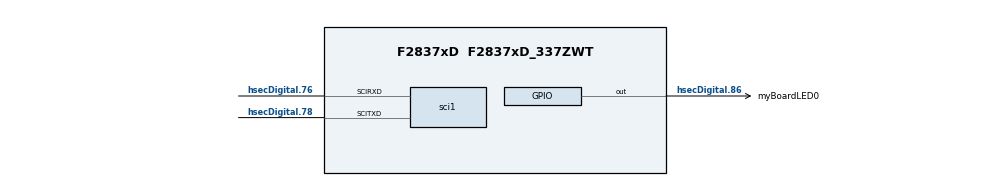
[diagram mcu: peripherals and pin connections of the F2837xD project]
/**
 * @cliArgs --board "/boards/TMDSCNCD28379D" --device "F2837xD" --part "F2837xD_337ZWT" --package "F2837xD_337ZWT" --context "CPU1" --product "C2000WARE@6.00.01.00"
 * @versions {"tool":"1.26.0+4407"}
 */

/**
 * Import the modules used in this configuration.
 */
const adc            = scripting.addModule("/driverlib/adc.js", {}, false);
const adc1           = adc.addInstance();
const adc2           = adc.addInstance();
const adc3           = adc.addInstance();
const adc4           = adc.addInstance();
const led            = scripting.addModule("/driverlib/board_components/led", {}, false);
const led1           = led.addInstance();
const device_support = scripting.addModule("/driverlib/device_support.js");
const epwm           = scripting.addModule("/driverlib/epwm.js", {}, false);
const epwm1          = epwm.addInstance();
const epwm2          = epwm.addInstance();
const epwm3          = epwm.addInstance();
const epwm4          = epwm.addInstance();
const epwm5          = epwm.addInstance();
const epwm6          = epwm.addInstance();
const epwm7          = epwm.addInstance();
const epwm8          = epwm.addInstance();
const inputxbar      = scripting.addModule("/driverlib/inputxbar.js", {}, false);
const inputxbar1     = inputxbar.addInstance();
const sci            = scripting.addModule("/driverlib/sci.js", {}, false);
const sci1           = sci.addInstance();

/**
 * Write custom configuration values to the imported modules.
 */
adc1.$name                   = "myADC0";
adc1.adcClockPrescaler       = "ADC_CLK_DIV_4_0";
adc1.enableInterrupt1        = true;
adc1.interruptPulseMode      = "ADC_PULSE_END_OF_CONV";
adc1.soc3SampleWindow        = 15;
adc1.soc4SampleWindow        = 15;
adc1.soc5SampleWindow        = 15;
adc1.soc6SampleWindow        = 15;
adc1.soc7SampleWindow        = 15;
adc1.soc8SampleWindow        = 15;
adc1.soc9SampleWindow        = 15;
adc1.soc10SampleWindow       = 15;
adc1.soc11SampleWindow       = 15;
adc1.soc12SampleWindow       = 15;
adc1.soc13SampleWindow       = 15;
adc1.soc14SampleWindow       = 15;
adc1.soc15SampleWindow       = 15;
adc1.soc0Trigger             = "ADC_TRIGGER_EPWM1_SOCA";
adc1.soc1Trigger             = "ADC_TRIGGER_EPWM1_SOCB";
adc1.enableInterrupt2        = true;
adc1.interrupt2SOCSource     = "ADC_SOC_NUMBER1";
adc1.soc2Trigger             = "ADC_TRIGGER_EPWM2_SOCA";
adc1.enableInterrupt3        = true;
adc1.interrupt3SOCSource     = "ADC_SOC_NUMBER2";
adc1.enabledSOCs             = ["ADC_SOC_NUMBER0","ADC_SOC_NUMBER1","ADC_SOC_NUMBER2"];
adc1.enabledInts             = ["ADC_INT_NUMBER1","ADC_INT_NUMBER2","ADC_INT_NUMBER3"];
adc1.registerInterrupts      = ["1","2","3"];
adc1.soc1Channel             = "ADC_CH_ADCIN2";
adc1.soc2Channel             = "ADC_CH_ADCIN4";
adc1.adcInt1.enableInterrupt = true;
adc1.adcInt2.enableInterrupt = true;
adc1.adcInt3.enableInterrupt = true;
scripting.suppress("SOC0 sample window must be at least 15", adc1, "soc0SampleWindow");
scripting.suppress("SOC1 sample window must be at least 15", adc1, "soc1SampleWindow");
scripting.suppress("SOC2 sample window must be at least 15", adc1, "soc2SampleWindow");

adc2.$name                   = "myADC1";
adc2.adcClockPrescaler       = "ADC_CLK_DIV_4_0";
adc2.enableInterrupt1        = true;
adc2.interruptPulseMode      = "ADC_PULSE_END_OF_CONV";
adc2.soc4SampleWindow        = 15;
adc2.soc5SampleWindow        = 15;
adc2.soc6SampleWindow        = 15;
adc2.soc7SampleWindow        = 15;
adc2.soc10SampleWindow       = 15;
adc2.soc11SampleWindow       = 15;
adc2.soc12SampleWindow       = 15;
adc2.soc13SampleWindow       = 15;
adc2.soc14SampleWindow       = 15;
adc2.soc15SampleWindow       = 15;
adc2.soc0Trigger             = "ADC_TRIGGER_EPWM1_SOCA";
adc2.soc1Channel             = "ADC_CH_ADCIN2";
adc2.soc1Trigger             = "ADC_TRIGGER_EPWM1_SOCB";
adc2.enableInterrupt2        = true;
adc2.soc2Channel             = "ADC_CH_ADCIN4";
adc2.soc2Trigger             = "ADC_TRIGGER_EPWM2_SOCA";
adc2.enableInterrupt3        = true;
adc2.adcBase                 = "ADCB_BASE";
adc2.enabledInts             = ["ADC_INT_NUMBER1","ADC_INT_NUMBER2","ADC_INT_NUMBER3"];
adc2.registerInterrupts      = ["1","2","3"];
adc2.enabledSOCs             = ["ADC_SOC_NUMBER3","ADC_SOC_NUMBER8","ADC_SOC_NUMBER9"];
adc2.soc3Trigger             = "ADC_TRIGGER_EPWM2_SOCB";
adc2.soc8Trigger             = "ADC_TRIGGER_EPWM5_SOCA";
adc2.soc9Trigger             = "ADC_TRIGGER_EPWM5_SOCB";
adc2.interrupt1SOCSource     = "ADC_SOC_NUMBER3";
adc2.interrupt2SOCSource     = "ADC_SOC_NUMBER8";
adc2.interrupt3SOCSource     = "ADC_SOC_NUMBER9";
adc2.soc8Channel             = "ADC_CH_ADCIN2";
adc2.soc9Channel             = "ADC_CH_ADCIN4";
adc2.adcInt1.enableInterrupt = true;
adc2.adcInt2.enableInterrupt = true;
adc2.adcInt3.enableInterrupt = true;
scripting.suppress("SOC3 sample window must be at least 15", adc2, "soc3SampleWindow");
scripting.suppress("SOC8 sample window must be at least 15", adc2, "soc8SampleWindow");
scripting.suppress("SOC9 sample window must be at least 15", adc2, "soc9SampleWindow");

adc3.$name                          = "myADC2";
adc3.adcClockPrescaler              = "ADC_CLK_DIV_4_0";
adc3.enableInterrupt1               = true;
adc3.interruptPulseMode             = "ADC_PULSE_END_OF_CONV";
adc3.soc3SampleWindow               = 15;
adc3.soc4SampleWindow               = 15;
adc3.soc5SampleWindow               = 15;
adc3.soc6SampleWindow               = 15;
adc3.soc7SampleWindow               = 15;
adc3.soc8SampleWindow               = 15;
adc3.soc9SampleWindow               = 15;
adc3.soc11SampleWindow              = 15;
adc3.soc13SampleWindow              = 15;
adc3.soc14SampleWindow              = 15;
adc3.soc15SampleWindow              = 15;
adc3.soc0Trigger                    = "ADC_TRIGGER_EPWM1_SOCA";
adc3.soc1Channel                    = "ADC_CH_ADCIN2";
adc3.soc1Trigger                    = "ADC_TRIGGER_EPWM1_SOCB";
adc3.enableInterrupt2               = true;
adc3.soc2Channel                    = "ADC_CH_ADCIN4";
adc3.soc2Trigger                    = "ADC_TRIGGER_EPWM2_SOCA";
adc3.enableInterrupt3               = true;
adc3.enableInterrupt3ContinuousMode = true;
adc3.interrupt3SOCSource            = "ADC_SOC_NUMBER2";
adc3.enabledInts                    = ["ADC_INT_NUMBER1","ADC_INT_NUMBER2"];
adc3.registerInterrupts             = ["1","2"];
adc3.adcBase                        = "ADCC_BASE";
adc3.soc12Channel                   = "ADC_CH_ADCIN4";
adc3.soc12Trigger                   = "ADC_TRIGGER_EPWM6_SOCB";
adc3.enabledSOCs                    = ["ADC_SOC_NUMBER10","ADC_SOC_NUMBER11"];
adc3.soc11Trigger                   = "ADC_TRIGGER_EPWM6_SOCB";
adc3.soc10Trigger                   = "ADC_TRIGGER_EPWM6_SOCA";
adc3.interrupt1SOCSource            = "ADC_SOC_NUMBER10";
adc3.interrupt2SOCSource            = "ADC_SOC_NUMBER11";
adc3.soc10Channel                   = "ADC_CH_ADCIN2";
adc3.soc11Channel                   = "ADC_CH_ADCIN4";
adc3.adcInt1.enableInterrupt        = true;
adc3.adcInt2.enableInterrupt        = true;
scripting.suppress("SOC10 sample window must be at least 15", adc3, "soc10SampleWindow");

adc4.$name                   = "myADC3";
adc4.adcClockPrescaler       = "ADC_CLK_DIV_4_0";
adc4.enableInterrupt1        = true;
adc4.interruptPulseMode      = "ADC_PULSE_END_OF_CONV";
adc4.soc3SampleWindow        = 15;
adc4.soc8SampleWindow        = 15;
adc4.soc9SampleWindow        = 15;
adc4.soc10SampleWindow       = 15;
adc4.soc11SampleWindow       = 15;
adc4.soc0Trigger             = "ADC_TRIGGER_EPWM1_SOCA";
adc4.soc1Channel             = "ADC_CH_ADCIN2";
adc4.soc1Trigger             = "ADC_TRIGGER_EPWM1_SOCB";
adc4.enableInterrupt2        = true;
adc4.soc2Channel             = "ADC_CH_ADCIN4";
adc4.soc2Trigger             = "ADC_TRIGGER_EPWM2_SOCA";
adc4.enableInterrupt3        = true;
adc4.adcBase                 = "ADCD_BASE";
adc4.enabledInts             = ["ADC_INT_NUMBER1","ADC_INT_NUMBER2","ADC_INT_NUMBER3","ADC_INT_NUMBER4"];
adc4.registerInterrupts      = ["1","2","3","4"];
adc4.enableInterrupt4        = true;
adc4.interrupt1SOCSource     = "ADC_SOC_NUMBER4";
adc4.interrupt2SOCSource     = "ADC_SOC_NUMBER5";
adc4.interrupt3SOCSource     = "ADC_SOC_NUMBER6";
adc4.interrupt4SOCSource     = "ADC_SOC_NUMBER7";
adc4.soc4Trigger             = "ADC_TRIGGER_EPWM3_SOCA";
adc4.soc5Channel             = "ADC_CH_ADCIN1";
adc4.soc5Trigger             = "ADC_TRIGGER_EPWM3_SOCB";
adc4.soc6Channel             = "ADC_CH_ADCIN2";
adc4.soc6Trigger             = "ADC_TRIGGER_EPWM4_SOCA";
adc4.soc7Channel             = "ADC_CH_ADCIN3";
adc4.soc7Trigger             = "ADC_TRIGGER_EPWM4_SOCB";
adc4.soc12Channel            = "ADC_CH_ADCIN4";
adc4.soc12Trigger            = "ADC_TRIGGER_EPWM7_SOCA";
adc4.soc13Channel            = "ADC_CH_ADCIN5";
adc4.soc13Trigger            = "ADC_TRIGGER_EPWM7_SOCB";
adc4.soc14Channel            = "ADC_CH_ADCIN14";
adc4.soc14Trigger            = "ADC_TRIGGER_EPWM8_SOCA";
adc4.soc15Channel            = "ADC_CH_ADCIN15";
adc4.soc15Trigger            = "ADC_TRIGGER_EPWM8_SOCB";
adc4.enabledSOCs             = ["ADC_SOC_NUMBER12","ADC_SOC_NUMBER13","ADC_SOC_NUMBER14","ADC_SOC_NUMBER15","ADC_SOC_NUMBER4","ADC_SOC_NUMBER5","ADC_SOC_NUMBER6","ADC_SOC_NUMBER7"];
adc4.adcInt1.enableInterrupt = true;
adc4.adcInt2.enableInterrupt = true;
adc4.adcInt3.enableInterrupt = true;
adc4.adcInt4.enableInterrupt = true;
scripting.suppress("SOC4 sample window must be at least 15", adc4, "soc4SampleWindow");
scripting.suppress("SOC5 sample window must be at least 15", adc4, "soc5SampleWindow");
scripting.suppress("SOC6 sample window must be at least 15", adc4, "soc6SampleWindow");
scripting.suppress("SOC7 sample window must be at least 15", adc4, "soc7SampleWindow");
scripting.suppress("SOC12 sample window must be at least 15", adc4, "soc12SampleWindow");
scripting.suppress("SOC13 sample window must be at least 15", adc4, "soc13SampleWindow");
scripting.suppress("SOC14 sample window must be at least 15", adc4, "soc14SampleWindow");
scripting.suppress("SOC15 sample window must be at least 15", adc4, "soc15SampleWindow");

led1.$name                = "myBoardLED0";
led1.$hardware            = system.deviceData.board.components.D2;
led1.gpio.gpioPin.$assign = "hsecDigital.86";

const divider3 = system.clockTree["EPWMCLKDIV"];
scripting.suppress("ePWM TZFRC and TZCLR events will sometimes be missed when EPWMCLKDIV is divide by 2\\. Always program EPWMCLKDIV to divide by 1 if using TZFRC or TZCLR register\\. Please refer to the F2837xD Silicon Errata for more details\\.", divider3, "EPWMCLK");

const multiplier4         = system.clockTree["PLL_IMULT"];
multiplier4.multiplyValue = 20;

const pinFunction3     = system.clockTree["XTAL"];
pinFunction3.XTAL_Freq = 20;

epwm1.$name                                                      = "myEPWM0";
epwm1.epwmTimebase_counterMode                                   = "EPWM_COUNTER_MODE_UP_DOWN";
epwm1.epwmTimebase_period                                        = 25000;
epwm1.epwmActionQualifier_EPWM_AQ_OUTPUT_A_shadowMode            = true;
epwm1.epwmActionQualifier_EPWM_AQ_OUTPUT_A_ON_TIMEBASE_UP_CMPA   = "EPWM_AQ_OUTPUT_HIGH";
epwm1.epwmActionQualifier_EPWM_AQ_OUTPUT_A_ON_TIMEBASE_DOWN_CMPA = "EPWM_AQ_OUTPUT_LOW";
epwm1.epwmActionQualifier_EPWM_AQ_OUTPUT_B_shadowMode            = true;
epwm1.epwmEventTrigger_EPWM_SOC_B_triggerEnable                  = true;
epwm1.epwmEventTrigger_EPWM_SOC_A_triggerEnable                  = true;
epwm1.epwmEventTrigger_EPWM_SOC_A_triggerEventCountInitEnable    = true;
epwm1.epwmEventTrigger_EPWM_SOC_B_triggerEventCountInitEnable    = true;
epwm1.epwmEventTrigger_EPWM_SOC_A_triggerEventCountInitForce     = true;
epwm1.epwmEventTrigger_EPWM_SOC_B_triggerEventCountInitForce     = true;
epwm1.epwmEventTrigger_EPWM_SOC_A_triggerSource                  = "EPWM_SOC_TBCTR_U_CMPA";
epwm1.epwmEventTrigger_EPWM_SOC_B_triggerSource                  = "EPWM_SOC_TBCTR_U_CMPB";
epwm1.epwmActionQualifier_EPWM_AQ_OUTPUT_B_ON_TIMEBASE_UP_CMPB   = "EPWM_AQ_OUTPUT_HIGH";
epwm1.epwmActionQualifier_EPWM_AQ_OUTPUT_B_ON_TIMEBASE_DOWN_CMPB = "EPWM_AQ_OUTPUT_LOW";
epwm1.epwmCounterCompare_cmpA                                    = 12500;
epwm1.epwmCounterCompare_cmpB                                    = 12500;
epwm1.$hardware                                                  = system.deviceData.board.components.PWM_LOC1;

epwm2.$name                                                      = "myEPWM1";
epwm2.epwmTimebase_counterMode                                   = "EPWM_COUNTER_MODE_UP_DOWN";
epwm2.epwmTimebase_period                                        = 25000;
epwm2.epwmActionQualifier_EPWM_AQ_OUTPUT_A_shadowMode            = true;
epwm2.epwmActionQualifier_EPWM_AQ_OUTPUT_A_ON_TIMEBASE_UP_CMPA   = "EPWM_AQ_OUTPUT_HIGH";
epwm2.epwmActionQualifier_EPWM_AQ_OUTPUT_A_ON_TIMEBASE_DOWN_CMPA = "EPWM_AQ_OUTPUT_LOW";
epwm2.epwmActionQualifier_EPWM_AQ_OUTPUT_B_shadowMode            = true;
epwm2.epwmEventTrigger_EPWM_SOC_B_triggerEnable                  = true;
epwm2.epwmEventTrigger_EPWM_SOC_A_triggerEnable                  = true;
epwm2.epwmEventTrigger_EPWM_SOC_A_triggerEventCountInitEnable    = true;
epwm2.epwmEventTrigger_EPWM_SOC_B_triggerEventCountInitEnable    = true;
epwm2.epwmEventTrigger_EPWM_SOC_A_triggerEventCountInitForce     = true;
epwm2.epwmEventTrigger_EPWM_SOC_B_triggerEventCountInitForce     = true;
epwm2.epwmEventTrigger_EPWM_SOC_A_triggerSource                  = "EPWM_SOC_TBCTR_U_CMPA";
epwm2.epwmEventTrigger_EPWM_SOC_B_triggerSource                  = "EPWM_SOC_TBCTR_U_CMPB";
epwm2.epwmActionQualifier_EPWM_AQ_OUTPUT_B_ON_TIMEBASE_UP_CMPB   = "EPWM_AQ_OUTPUT_HIGH";
epwm2.epwmActionQualifier_EPWM_AQ_OUTPUT_B_ON_TIMEBASE_DOWN_CMPB = "EPWM_AQ_OUTPUT_LOW";
epwm2.copyUse                                                    = true;
epwm2.copyFrom                                                   = "myEPWM0";
epwm2.$hardware                                                  = system.deviceData.board.components.PWM_LOC2;
epwm2.epwmCounterCompare_cmpA                                    = 12500;
epwm2.epwmCounterCompare_cmpB                                    = 12500;

epwm3.$name                                                      = "myEPWM2";
epwm3.epwmTimebase_counterMode                                   = "EPWM_COUNTER_MODE_UP_DOWN";
epwm3.epwmTimebase_period                                        = 25000;
epwm3.epwmActionQualifier_EPWM_AQ_OUTPUT_A_shadowMode            = true;
epwm3.epwmActionQualifier_EPWM_AQ_OUTPUT_A_ON_TIMEBASE_UP_CMPA   = "EPWM_AQ_OUTPUT_HIGH";
epwm3.epwmActionQualifier_EPWM_AQ_OUTPUT_A_ON_TIMEBASE_DOWN_CMPA = "EPWM_AQ_OUTPUT_LOW";
epwm3.epwmActionQualifier_EPWM_AQ_OUTPUT_B_shadowMode            = true;
epwm3.epwmEventTrigger_EPWM_SOC_B_triggerEnable                  = true;
epwm3.epwmEventTrigger_EPWM_SOC_A_triggerEnable                  = true;
epwm3.epwmEventTrigger_EPWM_SOC_A_triggerEventCountInitEnable    = true;
epwm3.epwmEventTrigger_EPWM_SOC_B_triggerEventCountInitEnable    = true;
epwm3.epwmEventTrigger_EPWM_SOC_A_triggerEventCountInitForce     = true;
epwm3.epwmEventTrigger_EPWM_SOC_B_triggerEventCountInitForce     = true;
epwm3.epwmEventTrigger_EPWM_SOC_A_triggerSource                  = "EPWM_SOC_TBCTR_U_CMPA";
epwm3.epwmEventTrigger_EPWM_SOC_B_triggerSource                  = "EPWM_SOC_TBCTR_U_CMPB";
epwm3.epwmActionQualifier_EPWM_AQ_OUTPUT_B_ON_TIMEBASE_UP_CMPB   = "EPWM_AQ_OUTPUT_HIGH";
epwm3.epwmActionQualifier_EPWM_AQ_OUTPUT_B_ON_TIMEBASE_DOWN_CMPB = "EPWM_AQ_OUTPUT_LOW";
epwm3.copyUse                                                    = true;
epwm3.copyFrom                                                   = "myEPWM0";
epwm3.$hardware                                                  = system.deviceData.board.components.PWM_LOC3;
epwm3.epwmCounterCompare_cmpA                                    = 12500;
epwm3.epwmCounterCompare_cmpB                                    = 12500;

epwm4.$name                                                      = "myEPWM3";
epwm4.epwmTimebase_counterMode                                   = "EPWM_COUNTER_MODE_UP_DOWN";
epwm4.epwmTimebase_period                                        = 25000;
epwm4.epwmActionQualifier_EPWM_AQ_OUTPUT_A_shadowMode            = true;
epwm4.epwmActionQualifier_EPWM_AQ_OUTPUT_A_ON_TIMEBASE_UP_CMPA   = "EPWM_AQ_OUTPUT_HIGH";
epwm4.epwmActionQualifier_EPWM_AQ_OUTPUT_A_ON_TIMEBASE_DOWN_CMPA = "EPWM_AQ_OUTPUT_LOW";
epwm4.epwmActionQualifier_EPWM_AQ_OUTPUT_B_shadowMode            = true;
epwm4.epwmEventTrigger_EPWM_SOC_B_triggerEnable                  = true;
epwm4.epwmEventTrigger_EPWM_SOC_A_triggerEnable                  = true;
epwm4.epwmEventTrigger_EPWM_SOC_A_triggerEventCountInitEnable    = true;
epwm4.epwmEventTrigger_EPWM_SOC_B_triggerEventCountInitEnable    = true;
epwm4.epwmEventTrigger_EPWM_SOC_A_triggerEventCountInitForce     = true;
epwm4.epwmEventTrigger_EPWM_SOC_B_triggerEventCountInitForce     = true;
epwm4.epwmEventTrigger_EPWM_SOC_A_triggerSource                  = "EPWM_SOC_TBCTR_U_CMPA";
epwm4.epwmEventTrigger_EPWM_SOC_B_triggerSource                  = "EPWM_SOC_TBCTR_U_CMPB";
epwm4.epwmActionQualifier_EPWM_AQ_OUTPUT_B_ON_TIMEBASE_UP_CMPB   = "EPWM_AQ_OUTPUT_HIGH";
epwm4.epwmActionQualifier_EPWM_AQ_OUTPUT_B_ON_TIMEBASE_DOWN_CMPB = "EPWM_AQ_OUTPUT_LOW";
epwm4.copyUse                                                    = true;
epwm4.copyFrom                                                   = "myEPWM0";
epwm4.$hardware                                                  = system.deviceData.board.components.PWM_LOC4;
epwm4.epwmCounterCompare_cmpA                                    = 12500;
epwm4.epwmCounterCompare_cmpB                                    = 12500;

epwm5.$name                                                      = "myEPWM4";
epwm5.epwmTimebase_counterMode                                   = "EPWM_COUNTER_MODE_UP_DOWN";
epwm5.epwmTimebase_period                                        = 25000;
epwm5.epwmActionQualifier_EPWM_AQ_OUTPUT_A_shadowMode            = true;
epwm5.epwmActionQualifier_EPWM_AQ_OUTPUT_A_ON_TIMEBASE_UP_CMPA   = "EPWM_AQ_OUTPUT_HIGH";
epwm5.epwmActionQualifier_EPWM_AQ_OUTPUT_A_ON_TIMEBASE_DOWN_CMPA = "EPWM_AQ_OUTPUT_LOW";
epwm5.epwmActionQualifier_EPWM_AQ_OUTPUT_B_shadowMode            = true;
epwm5.epwmEventTrigger_EPWM_SOC_B_triggerEnable                  = true;
epwm5.epwmEventTrigger_EPWM_SOC_A_triggerEnable                  = true;
epwm5.epwmEventTrigger_EPWM_SOC_A_triggerEventCountInitEnable    = true;
epwm5.epwmEventTrigger_EPWM_SOC_B_triggerEventCountInitEnable    = true;
epwm5.epwmEventTrigger_EPWM_SOC_A_triggerEventCountInitForce     = true;
epwm5.epwmEventTrigger_EPWM_SOC_B_triggerEventCountInitForce     = true;
epwm5.epwmEventTrigger_EPWM_SOC_A_triggerSource                  = "EPWM_SOC_TBCTR_U_CMPA";
epwm5.epwmEventTrigger_EPWM_SOC_B_triggerSource                  = "EPWM_SOC_TBCTR_U_CMPB";
epwm5.epwmActionQualifier_EPWM_AQ_OUTPUT_B_ON_TIMEBASE_UP_CMPB   = "EPWM_AQ_OUTPUT_HIGH";
epwm5.epwmActionQualifier_EPWM_AQ_OUTPUT_B_ON_TIMEBASE_DOWN_CMPB = "EPWM_AQ_OUTPUT_LOW";
epwm5.copyUse                                                    = true;
epwm5.copyFrom                                                   = "myEPWM0";
epwm5.$hardware                                                  = system.deviceData.board.components.PWM_LOC5;
epwm5.epwmCounterCompare_cmpA                                    = 12500;
epwm5.epwmCounterCompare_cmpB                                    = 12500;

epwm6.$name                                                      = "myEPWM5";
epwm6.epwmTimebase_counterMode                                   = "EPWM_COUNTER_MODE_UP_DOWN";
epwm6.epwmTimebase_period                                        = 25000;
epwm6.epwmActionQualifier_EPWM_AQ_OUTPUT_A_shadowMode            = true;
epwm6.epwmActionQualifier_EPWM_AQ_OUTPUT_A_ON_TIMEBASE_UP_CMPA   = "EPWM_AQ_OUTPUT_HIGH";
epwm6.epwmActionQualifier_EPWM_AQ_OUTPUT_A_ON_TIMEBASE_DOWN_CMPA = "EPWM_AQ_OUTPUT_LOW";
epwm6.epwmActionQualifier_EPWM_AQ_OUTPUT_B_shadowMode            = true;
epwm6.epwmEventTrigger_EPWM_SOC_B_triggerEnable                  = true;
epwm6.epwmEventTrigger_EPWM_SOC_A_triggerEnable                  = true;
epwm6.epwmEventTrigger_EPWM_SOC_A_triggerEventCountInitEnable    = true;
epwm6.epwmEventTrigger_EPWM_SOC_B_triggerEventCountInitEnable    = true;
epwm6.epwmEventTrigger_EPWM_SOC_A_triggerEventCountInitForce     = true;
epwm6.epwmEventTrigger_EPWM_SOC_B_triggerEventCountInitForce     = true;
epwm6.epwmEventTrigger_EPWM_SOC_A_triggerSource                  = "EPWM_SOC_TBCTR_U_CMPA";
epwm6.epwmEventTrigger_EPWM_SOC_B_triggerSource                  = "EPWM_SOC_TBCTR_U_CMPB";
epwm6.epwmActionQualifier_EPWM_AQ_OUTPUT_B_ON_TIMEBASE_UP_CMPB   = "EPWM_AQ_OUTPUT_HIGH";
epwm6.epwmActionQualifier_EPWM_AQ_OUTPUT_B_ON_TIMEBASE_DOWN_CMPB = "EPWM_AQ_OUTPUT_LOW";
epwm6.copyUse                                                    = true;
epwm6.copyFrom                                                   = "myEPWM0";
epwm6.$hardware                                                  = system.deviceData.board.components.PWM_LOC6;
epwm6.epwmCounterCompare_cmpA                                    = 12500;
epwm6.epwmCounterCompare_cmpB                                    = 12500;

epwm7.$name                                                      = "myEPWM6";
epwm7.epwmTimebase_counterMode                                   = "EPWM_COUNTER_MODE_UP_DOWN";
epwm7.epwmTimebase_period                                        = 25000;
epwm7.epwmActionQualifier_EPWM_AQ_OUTPUT_A_shadowMode            = true;
epwm7.epwmActionQualifier_EPWM_AQ_OUTPUT_A_ON_TIMEBASE_UP_CMPA   = "EPWM_AQ_OUTPUT_HIGH";
epwm7.epwmActionQualifier_EPWM_AQ_OUTPUT_A_ON_TIMEBASE_DOWN_CMPA = "EPWM_AQ_OUTPUT_LOW";
epwm7.epwmActionQualifier_EPWM_AQ_OUTPUT_B_shadowMode            = true;
epwm7.epwmEventTrigger_EPWM_SOC_B_triggerEnable                  = true;
epwm7.epwmEventTrigger_EPWM_SOC_A_triggerEnable                  = true;
epwm7.epwmEventTrigger_EPWM_SOC_A_triggerEventCountInitEnable    = true;
epwm7.epwmEventTrigger_EPWM_SOC_B_triggerEventCountInitEnable    = true;
epwm7.epwmEventTrigger_EPWM_SOC_A_triggerEventCountInitForce     = true;
epwm7.epwmEventTrigger_EPWM_SOC_B_triggerEventCountInitForce     = true;
epwm7.epwmEventTrigger_EPWM_SOC_A_triggerSource                  = "EPWM_SOC_TBCTR_U_CMPA";
epwm7.epwmEventTrigger_EPWM_SOC_B_triggerSource                  = "EPWM_SOC_TBCTR_U_CMPB";
epwm7.epwmActionQualifier_EPWM_AQ_OUTPUT_B_ON_TIMEBASE_UP_CMPB   = "EPWM_AQ_OUTPUT_HIGH";
epwm7.epwmActionQualifier_EPWM_AQ_OUTPUT_B_ON_TIMEBASE_DOWN_CMPB = "EPWM_AQ_OUTPUT_LOW";
epwm7.copyUse                                                    = true;
epwm7.copyFrom                                                   = "myEPWM0";
epwm7.$hardware                                                  = system.deviceData.board.components.PWM_LOC7;
epwm7.epwmCounterCompare_cmpA                                    = 12500;
epwm7.epwmCounterCompare_cmpB                                    = 12500;

epwm8.$name                                                      = "myEPWM7";
epwm8.epwmTimebase_counterMode                                   = "EPWM_COUNTER_MODE_UP_DOWN";
epwm8.epwmTimebase_period                                        = 25000;
epwm8.epwmActionQualifier_EPWM_AQ_OUTPUT_A_shadowMode            = true;
epwm8.epwmActionQualifier_EPWM_AQ_OUTPUT_A_ON_TIMEBASE_UP_CMPA   = "EPWM_AQ_OUTPUT_HIGH";
epwm8.epwmActionQualifier_EPWM_AQ_OUTPUT_A_ON_TIMEBASE_DOWN_CMPA = "EPWM_AQ_OUTPUT_LOW";
epwm8.epwmActionQualifier_EPWM_AQ_OUTPUT_B_shadowMode            = true;
epwm8.epwmEventTrigger_EPWM_SOC_B_triggerEnable                  = true;
epwm8.epwmEventTrigger_EPWM_SOC_A_triggerEnable                  = true;
epwm8.epwmEventTrigger_EPWM_SOC_A_triggerEventCountInitEnable    = true;
epwm8.epwmEventTrigger_EPWM_SOC_B_triggerEventCountInitEnable    = true;
epwm8.epwmEventTrigger_EPWM_SOC_A_triggerEventCountInitForce     = true;
epwm8.epwmEventTrigger_EPWM_SOC_B_triggerEventCountInitForce     = true;
epwm8.epwmEventTrigger_EPWM_SOC_A_triggerSource                  = "EPWM_SOC_TBCTR_U_CMPA";
epwm8.epwmEventTrigger_EPWM_SOC_B_triggerSource                  = "EPWM_SOC_TBCTR_U_CMPB";
epwm8.epwmActionQualifier_EPWM_AQ_OUTPUT_B_ON_TIMEBASE_UP_CMPB   = "EPWM_AQ_OUTPUT_HIGH";
epwm8.epwmActionQualifier_EPWM_AQ_OUTPUT_B_ON_TIMEBASE_DOWN_CMPB = "EPWM_AQ_OUTPUT_LOW";
epwm8.copyUse                                                    = true;
epwm8.copyFrom                                                   = "myEPWM0";
epwm8.$hardware                                                  = system.deviceData.board.components.PWM_LOC8;
epwm8.epwmCounterCompare_cmpA                                    = 12500;
epwm8.epwmCounterCompare_cmpB                                    = 12500;

inputxbar1.$name = "myINPUTXBAR0";

sci1.$name                 = "mySCI0";
sci1.enabledFIFOInterrupts = ["SCI_INT_RXFF","SCI_INT_TXFF"];
sci1.sci.$assign           = "SCIA";
sci1.sci.scirxdPin.$assign = "hsecDigital.76";
sci1.sci.scitxdPin.$assign = "hsecDigital.78";
sci1.rxQual.$name          = "myGPIOQUAL0";
sci1.txQual.$name          = "myGPIOQUAL1";
scripting.suppress("Connected to hardware,@@@.+?@@@ is connected to SCIA on the Control Card F28379D\\. Consider selecting it in \'use hardware\' above\\. @@@.+?@@@", sci1.sci, "scirxdPin");
scripting.suppress("Connected to hardware,@@@.+?@@@ is connected to SCIA on the Control Card F28379D\\. Consider selecting it in \'use hardware\' above\\. @@@.+?@@@", sci1.sci, "scitxdPin");

/**
 * Pinmux solution for unlocked pins/peripherals. This ensures that minor changes to the automatic solver in a future
 * version of the tool will not impact the pinmux you originally saw.  These lines can be completely deleted in order to
 * re-solve from scratch.
 */
epwm1.epwm.$suggestSolution           = "EPWM1";
epwm1.epwm.epwm_aPin.$suggestSolution = "hsecDigital.49";
epwm1.epwm.epwm_bPin.$suggestSolution = "hsecDigital.51";
epwm2.epwm.$suggestSolution           = "EPWM2";
epwm2.epwm.epwm_aPin.$suggestSolution = "hsecDigital.53";
epwm2.epwm.epwm_bPin.$suggestSolution = "hsecDigital.55";
epwm3.epwm.$suggestSolution           = "EPWM3";
epwm3.epwm.epwm_aPin.$suggestSolution = "hsecDigital.50";
epwm3.epwm.epwm_bPin.$suggestSolution = "hsecDigital.52";
epwm4.epwm.$suggestSolution           = "EPWM4";
epwm4.epwm.epwm_aPin.$suggestSolution = "hsecDigital.54";
epwm4.epwm.epwm_bPin.$suggestSolution = "hsecDigital.56";
epwm5.epwm.$suggestSolution           = "EPWM5";
epwm5.epwm.epwm_aPin.$suggestSolution = "hsecDigital.57";
epwm5.epwm.epwm_bPin.$suggestSolution = "hsecDigital.59";
epwm6.epwm.$suggestSolution           = "EPWM6";
epwm6.epwm.epwm_aPin.$suggestSolution = "hsecDigital.61";
epwm6.epwm.epwm_bPin.$suggestSolution = "hsecDigital.63";
epwm7.epwm.$suggestSolution           = "EPWM7";
epwm7.epwm.epwm_aPin.$suggestSolution = "hsecDigital.58";
epwm7.epwm.epwm_bPin.$suggestSolution = "hsecDigital.60";
epwm8.epwm.$suggestSolution           = "EPWM8";
epwm8.epwm.epwm_aPin.$suggestSolution = "hsecDigital.62";
epwm8.epwm.epwm_bPin.$suggestSolution = "hsecDigital.64";
